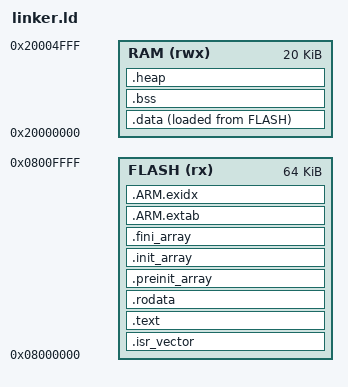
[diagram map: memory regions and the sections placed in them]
/*
 * Linker script for STM32F103C8T6 (Cortex-M3)
 * Flash: 64KB  @ 0x08000000
 * RAM:   20KB  @ 0x20000000
 */

ENTRY(Reset_Handler)

MEMORY
{
    FLASH (rx) : ORIGIN = 0x08000000, LENGTH = 64K
    RAM  (rwx) : ORIGIN = 0x20000000, LENGTH = 20K
}

/* Initial stack pointer: top of RAM (Cortex-M stack grows downward) */
_estack = ORIGIN(RAM) + LENGTH(RAM);

SECTIONS
{
    /* ----- Vector table (must be first in FLASH) ----- */
    .isr_vector :
    {
        . = ALIGN(4);
        KEEP(*(.isr_vector))
        . = ALIGN(4);
    } >FLASH

    /* ----- Code ----- */
    .text :
    {
        . = ALIGN(4);
        *(.text)
        *(.text*)
        . = ALIGN(4);
    } >FLASH

    /* ----- Read-only data ----- */
    .rodata :
    {
        . = ALIGN(4);
        *(.rodata)
        *(.rodata*)
        . = ALIGN(4);
    } >FLASH

    /* ----- C++ static constructors / destructors ----- */
    .preinit_array :
    {
        . = ALIGN(4);
        __preinit_array_start = .;
        KEEP(*(.preinit_array*))
        __preinit_array_end = .;
    } >FLASH

    .init_array :
    {
        . = ALIGN(4);
        __init_array_start = .;
        KEEP(*(SORT(.init_array.*)))
        KEEP(*(.init_array*))
        __init_array_end = .;
    } >FLASH

    .fini_array :
    {
        . = ALIGN(4);
        __fini_array_start = .;
        KEEP(*(SORT(.fini_array.*)))
        KEEP(*(.fini_array*))
        __fini_array_end = .;
    } >FLASH

    /* ----- ARM exception unwind tables ----- */
    .ARM.extab :
    {
        *(.ARM.extab* .gnu.linkonce.armextab.*)
    } >FLASH

    .ARM.exidx :
    {
        __exidx_start = .;
        *(.ARM.exidx* .gnu.linkonce.armexidx.*)
        __exidx_end = .;
    } >FLASH

    /* ----- Initialised data (load address in FLASH, runtime in RAM) ----- */
    _sidata = LOADADDR(.data);

    .data :
    {
        . = ALIGN(4);
        _sdata = .;
        *(.data)
        *(.data*)
        . = ALIGN(4);
        _edata = .;
    } >RAM AT>FLASH

    /* ----- Zero-initialised data (BSS) ----- */
    .bss :
    {
        . = ALIGN(4);
        _sbss = .;
        *(.bss)
        *(.bss*)
        *(COMMON)
        . = ALIGN(4);
        _ebss = .;
    } >RAM

    /* ----- Heap (reserved, 512 bytes by default) ----- */
    .heap (NOLOAD) :
    {
        . = ALIGN(8);
        _sheap = .;
        . = . + 0x200;
        . = ALIGN(8);
        _eheap = .;
    } >RAM

    /* ----- Discard metadata sections ----- */
    /DISCARD/ :
    {
        *(.note*)
        *(.comment*)
    }
}
